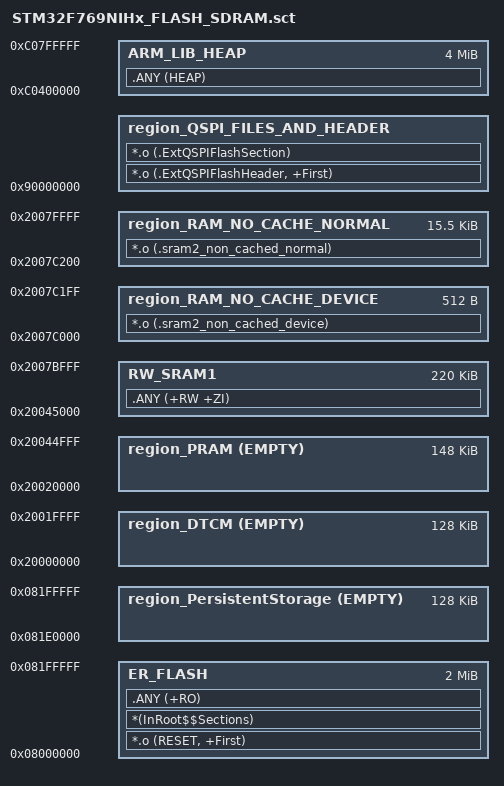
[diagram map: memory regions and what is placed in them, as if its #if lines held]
#! armcc -E
#include "../Config/assetConfig.h"

; *************************************************************
; *** Scatter-Loading Description File generated by uVision ***
; *************************************************************
/* Specify the memory areas */
/* ROM : [0x08000000,0x081FFFFF] : 2 MBytes                          */
/*       [0x08000000,0x080001FF] : 512 Bytes     : Interrrupt vectors */
/*       [0x08000200,0x081DFFFF] : 1919.5 KBytes : Code               */
/*       [0x081E0000,0x081FFFFF] : 128 KBytes    : Persistent storage */

/* DTCM : [0x20000000,0x2001FFFF] : 128K                              */

/* SRAM1 : [0x20020000,0x207BFFFF] : 368 KBytes                        */
/*         [0x20020000,0x20044FFF] : 148 KBytes   : PoolRAM  for audio */
/*         [0x20045000,0x2007BFFF] : 220 KBytes   : Variables          */

/* SRAM2 : [0x2007C000, 0x2007FFFF] : 16 KBytes                                 */
/*         [0x2007C000,0x2007C1FF]  : 512 Bytes     : Ethernet dma descripteurs */
/*         [0x2007C200,0x2007FFFF]  : 15.5 KBytes   : Ethernet Buffers          */

/* SDRAM : [0xC0400000, 0xC07FFFFF] : 4MBytes                                   */

/* QSPI  : [0x90000000, 0x00002000] : 8 KBytes      : Asset Headers             */
/* QSPI  : [0x90002000, 0x9FFFFFFF] : 255.99 MBytes : Asset Files               */

#define _DTCM_Length_  0x00020000
#define _PRAM_Length_  0x00025000


LR_FLASH 0x08000000   0x00200000 {  ; load region size_region
  ER_FLASH 0x08000000 0x00200000  {  ; load address = execution address
   *.o (RESET, +First)
   *(InRoot$$Sections)
   .ANY (+RO)
  }

ARM_LIB_HEAP 0xC0400000  0x00400000 { ; Whole SDRAM reserved for heap 
  .ANY (HEAP) 
 }                                               
										 
region_PersistentStorage 0x081E0000 EMPTY 0x0020000  { ; Credentials etc 
  }

region_DTCM 0x20000000 EMPTY _DTCM_Length_ { ; Fast RAM 
  }

region_PRAM 0x20020000 EMPTY _PRAM_Length_ { ; Pooled RAM
  }

RW_SRAM1 0x20045000 0x00037000  {  ; RW data
   .ANY (+RW +ZI)
  }

region_RAM_NO_CACHE_DEVICE 0x2007C000  0x00000200 { ; Ethernet DMA descriptors
 *.o (.sram2_non_cached_device)
  }

region_RAM_NO_CACHE_NORMAL 0x2007C200  0x00003E00 { ; Ethernet buffers
 *.o (.sram2_non_cached_normal)
  }
}

; Generate binary with assets  placed in QSPI, unless QSPI alreaday contains those assets 
#if defined(AVS_USE_QSPI) && defined(AVS_CREATE_QSPI_SECTION) 
QSPI 0x90000000  0x10000000 {  ; load region size_region
region_QSPI_FILES_AND_HEADER 0x90000000    { ; Asset Files & Headers
 *.o (.ExtQSPIFlashHeader, +First) ;; Insure header at 0x90000000
 *.o (.ExtQSPIFlashSection)
   }
}
#endif
